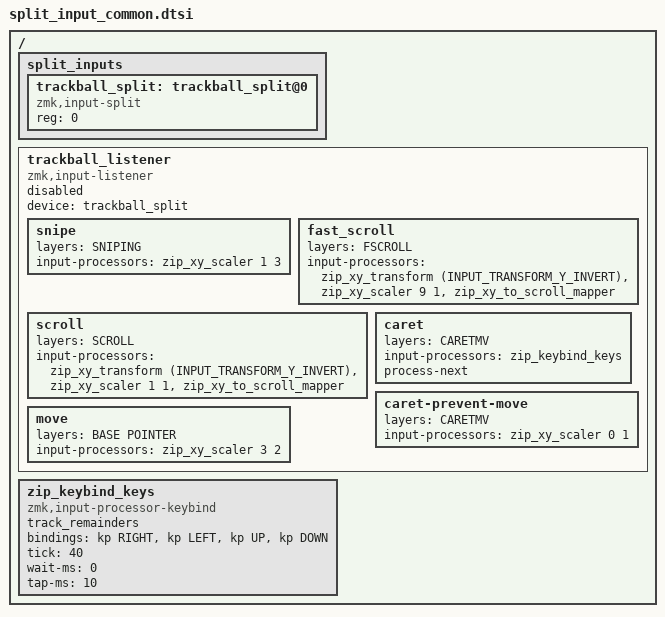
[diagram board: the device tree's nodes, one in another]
#include <dt-bindings/zmk/input_transform.h>
#include <input/processors.dtsi>
#include <input/processors/zmk-input-processor-keybind.dtsi>

// Layer definitions
#define BASE 0
#define POINTER 1
#define CARETMV 2
#define RAISE 3
#define SYMBOLS 4
#define SCROLL 5
#define FSCROLL 6
#define SNIPING 7

/ {
  split_inputs {
    #address-cells = <1>;
    #size-cells = <0>;

    trackball_split: trackball_split@0 {
      compatible = "zmk,input-split";
      reg = <0>;
    };
  };

  trackball_listener: trackball_listener {
    compatible = "zmk,input-listener";
    status = "disabled";
    device = <&trackball_split>;

    snipe {
      layers = <SNIPING>;
      input-processors = <&zip_xy_scaler 1 3>;
    };

    fast_scroll {
      layers = <FSCROLL>;
      input-processors = <&zip_xy_transform (INPUT_TRANSFORM_Y_INVERT)>, <&zip_xy_scaler 9 1>, <&zip_xy_to_scroll_mapper>;
    };

    scroll {
      layers = <SCROLL>;
      input-processors = <&zip_xy_transform (INPUT_TRANSFORM_Y_INVERT)>, <&zip_xy_scaler 1 1>, <&zip_xy_to_scroll_mapper>;
    };

    caret {
        layers = <CARETMV>;
        input-processors = <
            &zip_keybind_keys
        >;
        process-next;
    };
	
    caret-prevent-move {
        layers = <CARETMV>;
        input-processors = <&zip_xy_scaler 0 1>;
    };

    move {
      layers = <BASE POINTER>;
      input-processors = <&zip_xy_scaler 3 2>;
    };
  };

};

/ {
    zip_keybind_keys: zip_keybind_keys {
        compatible = "zmk,input-processor-keybind";
        #input-processor-cells = <0>;
        track_remainders;
        bindings = <&kp RIGHT>,
                  <&kp LEFT>,
                  <&kp UP>,
                  <&kp DOWN>;
        tick = <40>;
        wait-ms = <0>;
        tap-ms = <10>;
        // mode = <1>
        // threshold = <10>
        // max_threshold = <200>
        // max_pending_activations = <10>
    };
};
